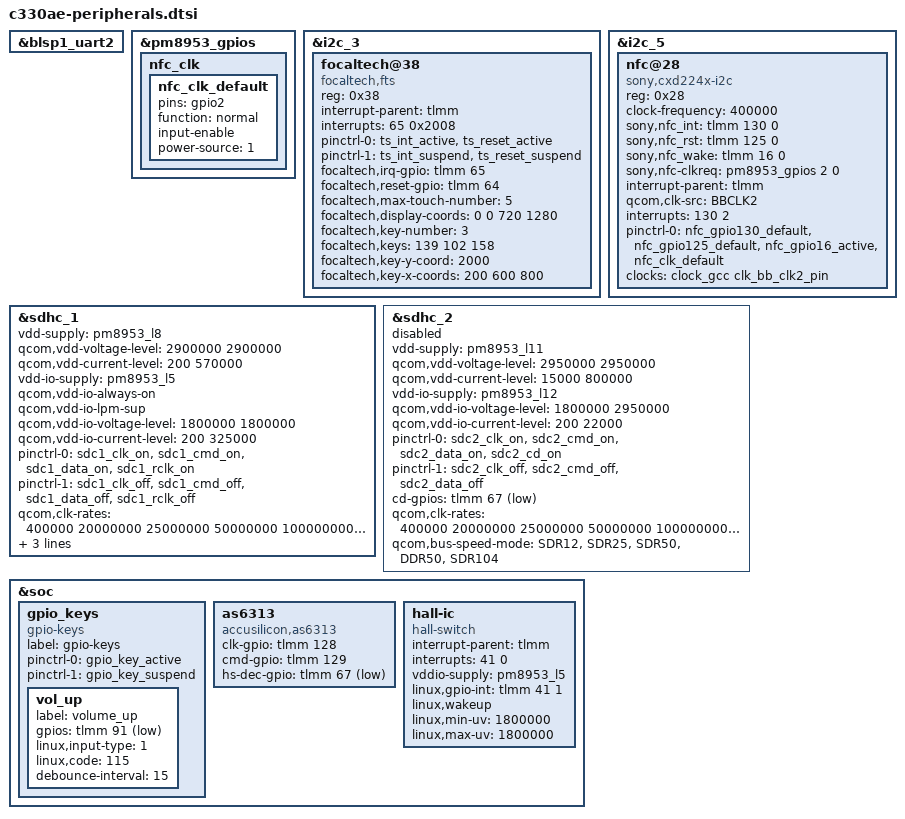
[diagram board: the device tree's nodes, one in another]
/* C330AE storage, keys, touch, NFC and small board peripherals. */

&blsp1_uart2 {
	status = "ok";
};

&pm8953_gpios {
	nfc_clk {
		nfc_clk_default: nfc_clk_default {
			pins = "gpio2";
			function = "normal";
			input-enable;
			power-source = <1>;
		};
	};
};

&i2c_3 {
	status = "ok";

	focaltech@38 {
		compatible = "focaltech,fts";
		reg = <0x38>;
		interrupt-parent = <&tlmm>;
		interrupts = <65 0x2008>;
		pinctrl-names = "pmx_ts_active", "pmx_ts_suspend";
		pinctrl-0 = <&ts_int_active &ts_reset_active>;
		pinctrl-1 = <&ts_int_suspend &ts_reset_suspend>;
		focaltech,irq-gpio = <&tlmm 65 0>;
		focaltech,reset-gpio = <&tlmm 64 0>;
		focaltech,max-touch-number = <5>;
		focaltech,display-coords = <0 0 720 1280>;
		focaltech,key-number = <3>;
		focaltech,keys = <139 102 158>;
		focaltech,key-y-coord = <2000>;
		focaltech,key-x-coords = <200 600 800>;
	};
};

&i2c_5 {
	status = "ok";

	nfc@28 {
		compatible = "sony,cxd224x-i2c";
		status = "ok";
		reg = <0x28>;
		clock-frequency = <400000>;
		sony,nfc_int = <&tlmm 130 0>;
		sony,nfc_rst = <&tlmm 125 0>;
		sony,nfc_wake = <&tlmm 16 0>;
		sony,nfc-clkreq = <&pm8953_gpios 2 0>;
		interrupt-parent = <&tlmm>;
		qcom,clk-src = "BBCLK2";
		interrupts = <130 2>;
		interrupt-names = "nfc_irq";
		pinctrl-names = "nfc_active";
		pinctrl-0 = <&nfc_gpio130_default &nfc_gpio125_default
			&nfc_gpio16_active &nfc_clk_default>;
		clocks = <&clock_gcc clk_bb_clk2_pin>;
		clock-names = "ref_clk";
	};
};

&sdhc_1 {
	vdd-supply = <&pm8953_l8>;
	qcom,vdd-voltage-level = <2900000 2900000>;
	qcom,vdd-current-level = <200 570000>;
	vdd-io-supply = <&pm8953_l5>;
	qcom,vdd-io-always-on;
	qcom,vdd-io-lpm-sup;
	qcom,vdd-io-voltage-level = <1800000 1800000>;
	qcom,vdd-io-current-level = <200 325000>;
	pinctrl-names = "active", "sleep";
	pinctrl-0 = <&sdc1_clk_on &sdc1_cmd_on &sdc1_data_on &sdc1_rclk_on>;
	pinctrl-1 = <&sdc1_clk_off &sdc1_cmd_off &sdc1_data_off &sdc1_rclk_off>;
	qcom,clk-rates = <400000 20000000 25000000 50000000
		100000000 192000000 384000000>;
	qcom,nonremovable;
	qcom,bus-speed-mode = "HS400_1p8v", "HS200_1p8v", "DDR_1p8v";
	status = "ok";
};

&sdhc_2 {
	vdd-supply = <&pm8953_l11>;
	qcom,vdd-voltage-level = <2950000 2950000>;
	qcom,vdd-current-level = <15000 800000>;
	vdd-io-supply = <&pm8953_l12>;
	qcom,vdd-io-voltage-level = <1800000 2950000>;
	qcom,vdd-io-current-level = <200 22000>;
	pinctrl-names = "active", "sleep";
	pinctrl-0 = <&sdc2_clk_on &sdc2_cmd_on &sdc2_data_on &sdc2_cd_on>;
	pinctrl-1 = <&sdc2_clk_off &sdc2_cmd_off &sdc2_data_off>;
	cd-gpios = <&tlmm 67 1>;
	qcom,clk-rates = <400000 20000000 25000000 50000000
		100000000 200000000>;
	qcom,bus-speed-mode = "SDR12", "SDR25", "SDR50", "DDR50", "SDR104";
	status = "disabled";
};

&soc {
	gpio_keys {
		compatible = "gpio-keys";
		label = "gpio-keys";
		pinctrl-names = "tlmm_gpio_key_active", "tlmm_gpio_key_suspend";
		pinctrl-0 = <&gpio_key_active>;
		pinctrl-1 = <&gpio_key_suspend>;

		vol_up {
			label = "volume_up";
			gpios = <&tlmm 91 1>;
			linux,input-type = <1>;
			linux,code = <115>;
			debounce-interval = <15>;
		};
	};

	as6313 {
		compatible = "accusilicon,as6313";
		clk-gpio = <&tlmm 128 0>;
		cmd-gpio = <&tlmm 129 0>;
		hs-dec-gpio = <&tlmm 67 1>;
	};

	hall-ic {
		compatible = "hall-switch";
		interrupt-parent = <&tlmm>;
		interrupts = <41 0>;
		vddio-supply = <&pm8953_l5>;
		linux,gpio-int = <&tlmm 41 1>;
		linux,wakeup;
		linux,min-uv = <1800000>;
		linux,max-uv = <1800000>;
	};
};
